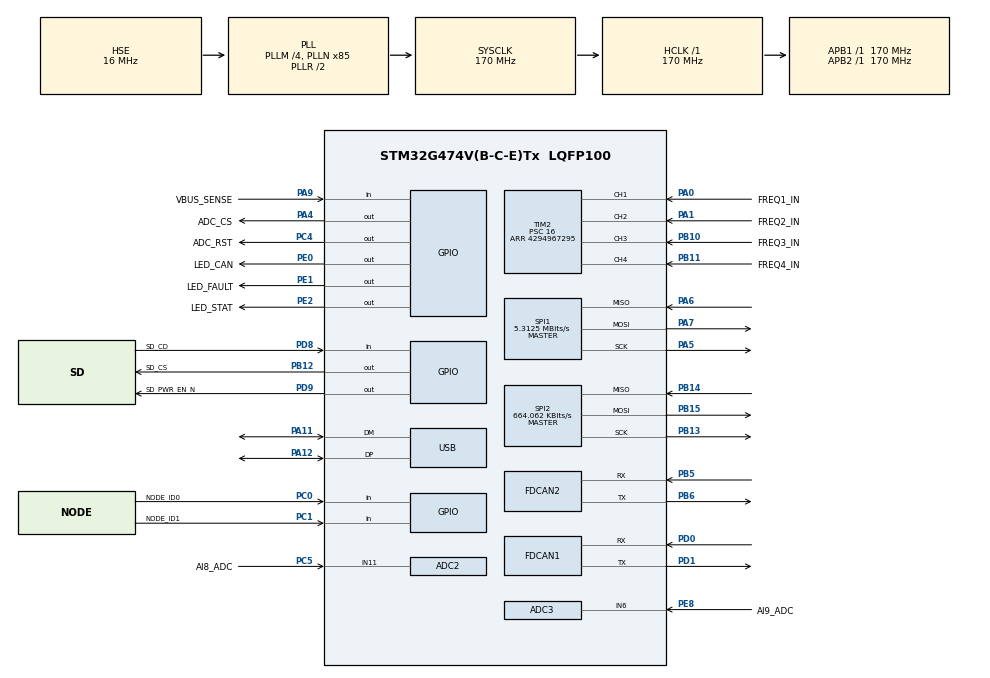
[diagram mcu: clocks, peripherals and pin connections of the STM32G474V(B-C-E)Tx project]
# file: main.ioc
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ADC2.Channel-0\#ChannelRegularConversion=ADC_CHANNEL_11
ADC2.NbrOfConversionFlag=1
ADC2.OffsetNumber-0\#ChannelRegularConversion=ADC_OFFSET_NONE
ADC2.Rank-0\#ChannelRegularConversion=1
ADC2.SamplingTime-0\#ChannelRegularConversion=ADC_SAMPLETIME_2CYCLES_5
ADC3.Channel-0\#ChannelRegularConversion=ADC_CHANNEL_6
ADC3.NbrOfConversionFlag=1
ADC3.OffsetNumber-0\#ChannelRegularConversion=ADC_OFFSET_NONE
ADC3.Rank-0\#ChannelRegularConversion=1
ADC3.SamplingTime-0\#ChannelRegularConversion=ADC_SAMPLETIME_2CYCLES_5
ADC3.master=1
FDCAN1.AutoRetransmission=ENABLE
FDCAN1.CalculateBaudRateNominal=500000
FDCAN1.CalculateTimeBitNominal=2000
FDCAN1.CalculateTimeQuantumNominal=125.0
FDCAN1.NominalPrescaler=2
FDCAN1.NominalSyncJumpWidth=2
FDCAN1.NominalTimeSeg1=13
FDCAN1.NominalTimeSeg2=2
FDCAN2.AutoRetransmission=ENABLE
FDCAN2.CalculateBaudRateNominal=500000
FDCAN2.CalculateTimeBitNominal=2000
FDCAN2.CalculateTimeQuantumNominal=125.0
FDCAN2.NominalPrescaler=2
FDCAN2.NominalSyncJumpWidth=2
FDCAN2.NominalTimeSeg1=13
FDCAN2.NominalTimeSeg2=2
Mcu.Family=STM32G4
Mcu.Name=STM32G474V(B-C-E)Tx
Mcu.Package=LQFP100
NVIC.FDCAN1_IT0_IRQn=true\:2\:0\:false\:false\:true\:true\:true\:true
NVIC.FDCAN2_IT0_IRQn=true\:2\:0\:false\:false\:true\:true\:true\:true
NVIC.PriorityGroup=NVIC_PRIORITYGROUP_4
NVIC.TIM2_IRQn=true\:0\:0\:false\:false\:true\:true\:true\:true
NVIC.TIM6_DAC_IRQn=true\:1\:0\:false\:false\:true\:false\:true\:true
PA0.GPIO_Label=FREQ1_IN
PA0.Signal=S_TIM2_CH1
PA1.GPIO_Label=FREQ2_IN
PA1.Signal=S_TIM2_CH2
PA11.Mode=Device
PA11.Signal=USB_DM
PA12.Mode=Device
PA12.Signal=USB_DP
PA13.Mode=Serial_Wire
PA13.Signal=SYS_JTMS-SWDIO
PA14.Mode=Serial_Wire
PA14.Signal=SYS_JTCK-SWCLK
PA4.GPIO_Label=ADC_CS
PA4.PinState=GPIO_PIN_SET
PA4.Signal=GPIO_Output
PA5.GPIO_Speed=GPIO_SPEED_FREQ_MEDIUM
PA5.Mode=Full_Duplex_Master
PA5.Signal=SPI1_SCK
PA6.GPIO_Speed=GPIO_SPEED_FREQ_MEDIUM
PA6.Mode=Full_Duplex_Master
PA6.Signal=SPI1_MISO
PA7.GPIO_Speed=GPIO_SPEED_FREQ_MEDIUM
PA7.Mode=Full_Duplex_Master
PA7.Signal=SPI1_MOSI
PA9.GPIO_Label=VBUS_SENSE
PA9.Signal=GPIO_Input
PB10.GPIO_Label=FREQ3_IN
PB10.Signal=S_TIM2_CH3
PB11.GPIO_Label=FREQ4_IN
PB11.Signal=S_TIM2_CH4
PB12.GPIO_Label=SD_CS
PB12.PinState=GPIO_PIN_SET
PB12.Signal=GPIO_Output
PB13.GPIO_Speed=GPIO_SPEED_FREQ_MEDIUM
PB13.Mode=Full_Duplex_Master
PB13.Signal=SPI2_SCK
PB14.GPIO_Speed=GPIO_SPEED_FREQ_MEDIUM
PB14.Mode=Full_Duplex_Master
PB14.Signal=SPI2_MISO
PB15.GPIO_Speed=GPIO_SPEED_FREQ_MEDIUM
PB15.Mode=Full_Duplex_Master
PB15.Signal=SPI2_MOSI
PB5.Mode=FDCAN_Activate
PB5.Signal=FDCAN2_RX
PB6.Mode=FDCAN_Activate
PB6.Signal=FDCAN2_TX
PC0.GPIO_Label=NODE_ID0
PC0.Signal=GPIO_Input
PC1.GPIO_Label=NODE_ID1
PC1.Signal=GPIO_Input
PC4.GPIO_Label=ADC_RST
PC4.PinState=GPIO_PIN_SET
PC4.Signal=GPIO_Output
PC5.GPIO_Label=AI8_ADC
PC5.Mode=IN11-Single-Ended
PC5.Signal=ADC2_IN11
PD0.Mode=FDCAN_Activate
PD0.Signal=FDCAN1_RX
PD1.Mode=FDCAN_Activate
PD1.Signal=FDCAN1_TX
PD8.GPIO_Label=SD_CD
PD8.Signal=GPIO_Input
PD9.GPIO_Label=SD_PWR_EN_N
PD9.Signal=GPIO_Output
PE0.GPIO_Label=LED_CAN
PE0.Signal=GPIO_Output
PE1.GPIO_Label=LED_FAULT
PE1.Signal=GPIO_Output
PE2.GPIO_Label=LED_STAT
PE2.Signal=GPIO_Output
PE8.GPIO_Label=AI9_ADC
PE8.Mode=IN6-Single-Ended
PE8.Signal=ADC3_IN6
PF0-OSC_IN.Mode=HSE-External-Oscillator
PF0-OSC_IN.Signal=RCC_OSC_IN
PF1-OSC_OUT.Mode=HSE-External-Oscillator
PF1-OSC_OUT.Signal=RCC_OSC_OUT
ProjectManager.HeapSize=0x1000
ProjectManager.StackSize=0x1000
ProjectManager.TargetToolchain=STM32CubeIDE
RCC.ADC12Freq_Value=170000000
RCC.ADC345Freq_Value=170000000
RCC.AHBFreq_Value=170000000
RCC.APB1Freq_Value=170000000
RCC.APB1TimFreq_Value=170000000
RCC.APB2Freq_Value=170000000
RCC.APB2TimFreq_Value=170000000
RCC.CK48CLockSelection=RCC_USBCLKSOURCE_HSI48
RCC.CortexFreq_Value=170000000
RCC.EXTERNAL_CLOCK_VALUE=12288000
RCC.FDCANCLockSelection=RCC_FDCANCLKSOURCE_HSE
RCC.HCLKFreq_Value=170000000
RCC.HSE_VALUE=16000000
RCC.HSI48_VALUE=48000000
RCC.HSI_VALUE=16000000
RCC.LSE_VALUE=32768
RCC.PLLM=RCC_PLLM_DIV4
RCC.PLLN=85
RCC.PLLQ=RCC_PLLQ_DIV4
RCC.PLLSourceVirtual=RCC_PLLSOURCE_HSE
RCC.SYSCLKFreq_VALUE=170000000
RCC.SYSCLKSource=RCC_SYSCLKSOURCE_PLLCLK
RCC.USBFreq_Value=48000000
RCC.VCOOutputFreq_Value=340000000
SH.S_TIM2_CH1.0=TIM2_CH1,Input_Capture1_from_TI1
SH.S_TIM2_CH2.0=TIM2_CH2,Input_Capture2_from_TI2
SH.S_TIM2_CH3.0=TIM2_CH3,Input_Capture3_from_TI3
SH.S_TIM2_CH4.0=TIM2_CH4,Input_Capture4_from_TI4
SPI1.BaudRatePrescaler=SPI_BAUDRATEPRESCALER_32
SPI1.CLKPhase=SPI_PHASE_2EDGE
SPI1.CLKPolarity=SPI_POLARITY_LOW
SPI1.CalculateBaudRate=5.3125 MBits/s
SPI1.DataSize=SPI_DATASIZE_16BIT
SPI1.Direction=SPI_DIRECTION_2LINES
SPI1.Mode=SPI_MODE_MASTER
SPI1.VirtualType=VM_MASTER
SPI2.BaudRatePrescaler=SPI_BAUDRATEPRESCALER_256
SPI2.CalculateBaudRate=664.062 KBits/s
SPI2.DataSize=SPI_DATASIZE_8BIT
SPI2.Direction=SPI_DIRECTION_2LINES
SPI2.Mode=SPI_MODE_MASTER
SPI2.VirtualType=VM_MASTER
TIM2.Channel-Input_Capture1_from_TI1=TIM_CHANNEL_1
TIM2.Channel-Input_Capture2_from_TI2=TIM_CHANNEL_2
TIM2.Channel-Input_Capture3_from_TI3=TIM_CHANNEL_3
TIM2.Channel-Input_Capture4_from_TI4=TIM_CHANNEL_4
TIM2.ICPolarity_CH1=TIM_INPUTCHANNELPOLARITY_RISING
TIM2.ICPolarity_CH2=TIM_INPUTCHANNELPOLARITY_RISING
TIM2.ICPolarity_CH3=TIM_INPUTCHANNELPOLARITY_RISING
TIM2.ICPolarity_CH4=TIM_INPUTCHANNELPOLARITY_RISING
TIM2.Period=4294967295
TIM2.Prescaler=16
TIM6.AutoReloadPreload=TIM_AUTORELOAD_PRELOAD_ENABLE
TIM6.CounterMode=TIM_COUNTERMODE_UP
TIM6.Dithering=Disable
TIM6.PeriodNoDither=999
TIM6.Prescaler=169
TIM6.TIM_MasterOutputTrigger=TIM_TRGO_RESET
VP_FATFS_VS_Generic.Mode=User_defined
VP_SYS_VS_DBSignals.Mode=DisableDeadBatterySignals
VP_TIM6_VS_ClockSourceINT.Mode=Enable_Timer
board=custom

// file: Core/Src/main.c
/* USER CODE BEGIN Header */
/**
  ******************************************************************************
  * @file           : main.c
  * @brief          : Main program body
  ******************************************************************************
  * @attention
  *
  * Copyright (c) 2026 STMicroelectronics.
  * All rights reserved.
  *
  * This software is licensed under terms that can be found in the LICENSE file
  * in the root directory of this software component.
  * If no LICENSE file comes with this software, it is provided AS-IS.
  *
  ******************************************************************************
  */
/* USER CODE END Header */
#include "main.h"
#include "adc.h"
#include "app_fatfs.h"
#include "fdcan.h"
#include "spi.h"
#include "tim.h"
#include "usb.h"
#include "gpio.h"

/* USER CODE BEGIN Includes */
#include "app.h"
/* USER CODE END Includes */

void SystemClock_Config(void);

int main(void)
{

  /* MCU Configuration--------------------------------------------------------*/

  /* Reset of all peripherals, Initializes the Flash interface and the Systick. */
  HAL_Init();

  /* Configure the system clock */
  SystemClock_Config();

  /* USER CODE BEGIN SysInit */
  /* USB runs from HSI48 (no 48 MHz from the PLL with a 16 MHz HSE at 170 MHz).
   * HSI48 alone is not accurate enough for USB full speed, so lock it to the
   * host's 1 kHz start-of-frame packets with the clock recovery system (CRS). */
  {
    RCC_CRSInitTypeDef crs = {0};
    __HAL_RCC_CRS_CLK_ENABLE();
    crs.Prescaler             = RCC_CRS_SYNC_DIV1;
    crs.Source                = RCC_CRS_SYNC_SOURCE_USB;
    crs.Polarity              = RCC_CRS_SYNC_POLARITY_RISING;
    crs.ReloadValue           = __HAL_RCC_CRS_RELOADVALUE_CALCULATE(48000000U, 1000U);
    crs.ErrorLimitValue       = RCC_CRS_ERRORLIMIT_DEFAULT;
    crs.HSI48CalibrationValue = RCC_CRS_HSI48CALIBRATION_DEFAULT;
    HAL_RCCEx_CRSConfig(&crs);
  }
  /* USER CODE END SysInit */

  /* Initialize all configured peripherals */
  MX_GPIO_Init();
  MX_ADC2_Init();
  MX_ADC3_Init();
  MX_FDCAN1_Init();
  MX_FDCAN2_Init();
  MX_SPI1_Init();
  MX_SPI2_Init();
  MX_USB_PCD_Init();
  MX_TIM2_Init();
  MX_TIM6_Init();
  if (MX_FATFS_Init() != APP_OK) {
    Error_Handler();
  }
  /* USER CODE BEGIN 2 */
  app_init();
  /* USER CODE END 2 */

  /* Infinite loop */
  while (1)
  {

    /* USER CODE BEGIN 3 */
    app_loop();
  }
  /* USER CODE END 3 */
}

void SystemClock_Config(void)
{
  RCC_OscInitTypeDef RCC_OscInitStruct = {0};
  RCC_ClkInitTypeDef RCC_ClkInitStruct = {0};

  /** Configure the main internal regulator output voltage
  */
  HAL_PWREx_ControlVoltageScaling(PWR_REGULATOR_VOLTAGE_SCALE1_BOOST);

  /** Initializes the RCC Oscillators according to the specified parameters
  * in the RCC_OscInitTypeDef structure.
  */
  RCC_OscInitStruct.OscillatorType = RCC_OSCILLATORTYPE_HSI48|RCC_OSCILLATORTYPE_HSE;
  RCC_OscInitStruct.HSEState = RCC_HSE_ON;
  RCC_OscInitStruct.HSI48State = RCC_HSI48_ON;
  RCC_OscInitStruct.PLL.PLLState = RCC_PLL_ON;
  RCC_OscInitStruct.PLL.PLLSource = RCC_PLLSOURCE_HSE;
  RCC_OscInitStruct.PLL.PLLM = RCC_PLLM_DIV4;
  RCC_OscInitStruct.PLL.PLLN = 85;
  RCC_OscInitStruct.PLL.PLLP = RCC_PLLP_DIV2;
  RCC_OscInitStruct.PLL.PLLQ = RCC_PLLQ_DIV4;
  RCC_OscInitStruct.PLL.PLLR = RCC_PLLR_DIV2;
  if (HAL_RCC_OscConfig(&RCC_OscInitStruct) != HAL_OK)
  {
    Error_Handler();
  }

  /** Initializes the CPU, AHB and APB buses clocks
  */
  RCC_ClkInitStruct.ClockType = RCC_CLOCKTYPE_HCLK|RCC_CLOCKTYPE_SYSCLK
                              |RCC_CLOCKTYPE_PCLK1|RCC_CLOCKTYPE_PCLK2;
  RCC_ClkInitStruct.SYSCLKSource = RCC_SYSCLKSOURCE_PLLCLK;
  RCC_ClkInitStruct.AHBCLKDivider = RCC_SYSCLK_DIV1;
  RCC_ClkInitStruct.APB1CLKDivider = RCC_HCLK_DIV1;
  RCC_ClkInitStruct.APB2CLKDivider = RCC_HCLK_DIV1;

  if (HAL_RCC_ClockConfig(&RCC_ClkInitStruct, FLASH_LATENCY_4) != HAL_OK)
  {
    Error_Handler();
  }
}

void Error_Handler(void)
{
  __disable_irq();
  while (1)
  {
  }
}
